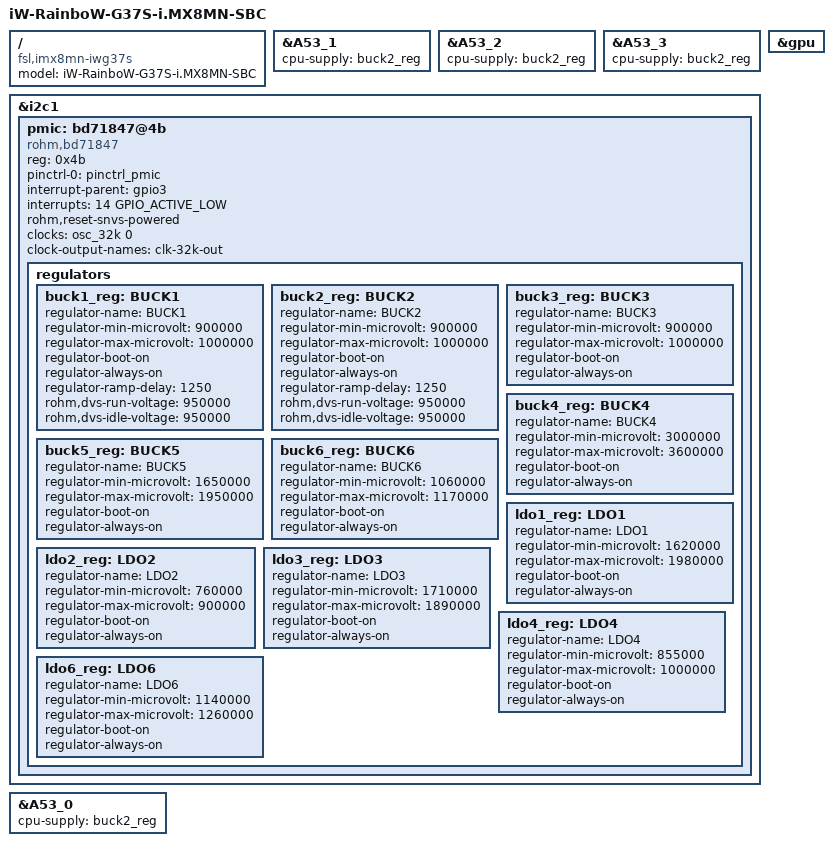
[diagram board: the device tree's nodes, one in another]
/*
 * Copyright (c) 2022-23 iWave Systems Technologies Pvt. Ltd.
 *
 * This program is free software; you can redistribute it and/or
 * modify it under the terms of the GNU General Public License
 * as published by the Free Software Foundation; either version 2
 * of the License, or (at your option) any later version.
 *
 * This program is distributed in the hope that it will be useful,
 * but WITHOUT ANY WARRANTY; without even the implied warranty of
 * MERCHANTABILITY or FITNESS FOR A PARTICULAR PURPOSE.  See the
 * GNU General Public License for more details.
 */

/dts-v1/;

#include "imx8mn.dtsi"
#include "imx8mn-iwg37s.dtsi"
#include <dt-bindings/interrupt-controller/irq.h>

/ {
	model = "iW-RainboW-G37S-i.MX8MN-SBC";
	compatible = "fsl,imx8mn-iwg37s", "fsl,imx8mn";
};

&A53_1 {
        cpu-supply = <&buck2_reg>;
};

&A53_2 {
        cpu-supply = <&buck2_reg>;
};

&A53_3 {
        cpu-supply = <&buck2_reg>;
};

&i2c1 { /* I2C1 bus */
	pmic: bd71847@4b { /* PMIC: PMIC BD71847MWV */
		compatible = "rohm,bd71847";
		reg = <0x4b>;
		pinctrl-names = "default";
		pinctrl-0 = <&pinctrl_pmic>;
		interrupt-parent = <&gpio3>;
		interrupts = <14 GPIO_ACTIVE_LOW>;
		rohm,reset-snvs-powered;

		#clock-cells = <0>;
		clocks = <&osc_32k 0>;
		clock-output-names = "clk-32k-out";
		status = "okay";

		regulators {
			buck1_reg: BUCK1 {
				regulator-name = "BUCK1";
				regulator-min-microvolt = <900000>;
				regulator-max-microvolt = <1000000>;
				regulator-boot-on;
				regulator-always-on;
				regulator-ramp-delay = <1250>;
				rohm,dvs-run-voltage = <950000>;
				rohm,dvs-idle-voltage = <950000>;
			};

		       buck2_reg: BUCK2 {
				regulator-name = "BUCK2";
				regulator-min-microvolt = <900000>;
				regulator-max-microvolt = <1000000>;
				regulator-boot-on;
				regulator-always-on;
				regulator-ramp-delay = <1250>;
				rohm,dvs-run-voltage = <950000>;
				rohm,dvs-idle-voltage = <950000>;
			};

			buck3_reg: BUCK3 {
				regulator-name = "BUCK3";
				regulator-min-microvolt = <900000>;
				regulator-max-microvolt = <1000000>;
				regulator-boot-on;
				regulator-always-on;
			};

			buck4_reg: BUCK4 {
				regulator-name = "BUCK4";
				regulator-min-microvolt = <3000000>;
				regulator-max-microvolt = <3600000>;
				regulator-boot-on;
				regulator-always-on;
			};

			buck5_reg: BUCK5 {
				regulator-name = "BUCK5";
				regulator-min-microvolt = <1650000>;
				regulator-max-microvolt = <1950000>;
				regulator-boot-on;
				regulator-always-on;
			};

			buck6_reg: BUCK6 {
				regulator-name = "BUCK6";
				regulator-min-microvolt = <1060000>;
				regulator-max-microvolt = <1170000>;
				regulator-boot-on;
				regulator-always-on;
			};

			ldo1_reg: LDO1 {
				regulator-name = "LDO1";
				regulator-min-microvolt = <1620000>;
				regulator-max-microvolt = <1980000>;
				regulator-boot-on;
				regulator-always-on;
			};

			ldo2_reg: LDO2 {
				regulator-name = "LDO2";
				regulator-min-microvolt = <760000>;
				regulator-max-microvolt = <900000>;
				regulator-boot-on;
				regulator-always-on;
			};

			ldo3_reg: LDO3 {
				regulator-name = "LDO3";
				regulator-min-microvolt = <1710000>;
				regulator-max-microvolt = <1890000>;
				regulator-boot-on;
				regulator-always-on;
			};

			ldo4_reg: LDO4 {
				regulator-name = "LDO4";
				regulator-min-microvolt = <855000>;
				regulator-max-microvolt = <1000000>;
				regulator-boot-on;
				regulator-always-on;
			};

			ldo6_reg: LDO6 {
				regulator-name = "LDO6";
				regulator-min-microvolt = <1140000>;
				regulator-max-microvolt = <1260000>;
				regulator-boot-on;
				regulator-always-on;
			};
		};
	};
};

&A53_0 {
	cpu-supply = <&buck2_reg>;
};

&gpu { /* GPU */
	status= "okay";
};
